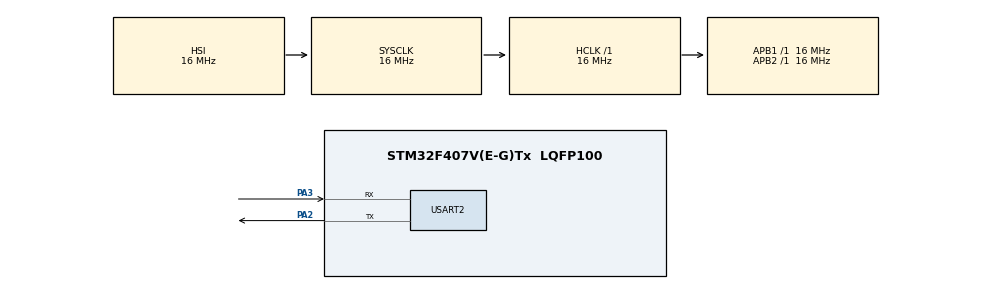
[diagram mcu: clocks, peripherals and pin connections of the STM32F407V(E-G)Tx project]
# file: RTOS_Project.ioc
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Mcu.Family=STM32F4
Mcu.Name=STM32F407V(E-G)Tx
Mcu.Package=LQFP100
NVIC.PriorityGroup=NVIC_PRIORITYGROUP_4
PA13.Mode=Serial_Wire
PA13.Signal=SYS_JTMS-SWDIO
PA14.Mode=Serial_Wire
PA14.Signal=SYS_JTCK-SWCLK
PA2.Mode=Asynchronous
PA2.Signal=USART2_TX
PA3.Mode=Asynchronous
PA3.Signal=USART2_RX
PH0-OSC_IN.Mode=HSE-External-Oscillator
PH0-OSC_IN.Signal=RCC_OSC_IN
PH1-OSC_OUT.Mode=HSE-External-Oscillator
PH1-OSC_OUT.Signal=RCC_OSC_OUT
ProjectManager.HeapSize=0x200
ProjectManager.StackSize=0x400
ProjectManager.TargetToolchain=STM32CubeIDE
RCC.AHBFreq_Value=16000000
RCC.APB1Freq_Value=16000000
RCC.APB2Freq_Value=16000000
RCC.CortexFreq_Value=16000000
RCC.HSE_VALUE=25000000
RCC.HSI_VALUE=16000000
RCC.LSE_VALUE=32768
RCC.SYSCLKFreq_VALUE=16000000
RCC.VCOOutputFreq_Value=192000000
USART2.VirtualMode=VM_ASYNC
board=custom

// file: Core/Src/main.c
/* USER CODE BEGIN Header */
/**
  ******************************************************************************
  * @file           : main.c
  * @brief          : Main program body
  ******************************************************************************
  * @attention
  *
  * <h2><center>&copy; Copyright (c) 2021 STMicroelectronics.
  * All rights reserved.</center></h2>
  *
  * This software component is licensed by ST under BSD 3-Clause license,
  * the "License"; You may not use this file except in compliance with the
  * License. You may obtain a copy of the License at:
  *                        opensource.org/licenses/BSD-3-Clause
  *
  ******************************************************************************
  */
/* USER CODE END Header */
#include "main.h"

/* USER CODE BEGIN Includes */
#include <stdio.h>
#include "FreeRTOS.h"
#include "task.h"
#include "queue.h"

/* USER CODE END Includes */

 UART_HandleTypeDef huart2;

/* USER CODE BEGIN PV */
 TaskHandle_t task1_handle;
 TaskHandle_t task2_handle;
 QueueHandle_t xQueue1;

/* USER CODE END PV */

void SystemClock_Config(void);
static void MX_GPIO_Init(void);
static void MX_USART2_UART_Init(void);
/* USER CODE BEGIN PFP */
void task1_handler(void* parameters);
void task2_handler(void* parameters);

extern  void SEGGER_UART_init(uint32_t);

#ifdef __GNUC__
#define PUTCHAR_PROTOTYPE int __io_putchar(int ch)
#else
#define PUTCHAR_PROTOTYPE int fputc(int ch, FILE *f)
#endif /* __GNUC__ */

/**
  * @brief  Retargets the C library printf function to the USART.
  * @param  None
  * @retval None
  */
PUTCHAR_PROTOTYPE
{
  HAL_UART_Transmit(&huart2, (uint8_t *)&ch, 1, HAL_MAX_DELAY);
  return ch;
}

/* USER CODE END PFP */

int main(void)
{
  /* USER CODE BEGIN 1 */

	BaseType_t status;

  /* USER CODE END 1 */

  /* MCU Configuration--------------------------------------------------------*/

  /* Reset of all peripherals, Initializes the Flash interface and the Systick. */
  HAL_Init();

  /* Configure the system clock */
  SystemClock_Config();

  /* Initialize all configured peripherals */
  MX_GPIO_Init();
  MX_USART2_UART_Init();
  /* USER CODE BEGIN 2 */

  status = xTaskCreate(task1_handler, "Task-1", 200, "Hello world from Task-1", 2, &task1_handle);

  configASSERT(status == pdPASS);

  status = xTaskCreate(task2_handler, "Task-2", 200, "Hello world from Task-2", 2, &task2_handle);

  configASSERT(status == pdPASS);

  xQueue1 = xQueueCreate(5, sizeof(uint8_t) );

  //start the freeRTOS scheduler
  vTaskStartScheduler();
  /* USER CODE END 2 */

  /* Infinite loop */
  while (1)
  {

  }
}

void SystemClock_Config(void)
{
  RCC_OscInitTypeDef RCC_OscInitStruct = {0};
  RCC_ClkInitTypeDef RCC_ClkInitStruct = {0};

  /** Configure the main internal regulator output voltage
  */
  __HAL_RCC_PWR_CLK_ENABLE();
  __HAL_PWR_VOLTAGESCALING_CONFIG(PWR_REGULATOR_VOLTAGE_SCALE1);

  /** Initializes the RCC Oscillators according to the specified parameters
  * in the RCC_OscInitTypeDef structure.
  */
  RCC_OscInitStruct.OscillatorType = RCC_OSCILLATORTYPE_HSI;
  RCC_OscInitStruct.HSIState = RCC_HSI_ON;
  RCC_OscInitStruct.HSICalibrationValue = RCC_HSICALIBRATION_DEFAULT;
  RCC_OscInitStruct.PLL.PLLState = RCC_PLL_NONE;
  if (HAL_RCC_OscConfig(&RCC_OscInitStruct) != HAL_OK)
  {
    Error_Handler();
  }

  /** Initializes the CPU, AHB and APB buses clocks
  */
  RCC_ClkInitStruct.ClockType = RCC_CLOCKTYPE_HCLK|RCC_CLOCKTYPE_SYSCLK
                              |RCC_CLOCKTYPE_PCLK1|RCC_CLOCKTYPE_PCLK2;
  RCC_ClkInitStruct.SYSCLKSource = RCC_SYSCLKSOURCE_HSI;
  RCC_ClkInitStruct.AHBCLKDivider = RCC_SYSCLK_DIV1;
  RCC_ClkInitStruct.APB1CLKDivider = RCC_HCLK_DIV1;
  RCC_ClkInitStruct.APB2CLKDivider = RCC_HCLK_DIV1;

  if (HAL_RCC_ClockConfig(&RCC_ClkInitStruct, FLASH_LATENCY_0) != HAL_OK)
  {
    Error_Handler();
  }
}

static void MX_USART2_UART_Init(void)
{

  huart2.Instance = USART2;
  huart2.Init.BaudRate = 115200;
  huart2.Init.WordLength = UART_WORDLENGTH_8B;
  huart2.Init.StopBits = UART_STOPBITS_1;
  huart2.Init.Parity = UART_PARITY_NONE;
  huart2.Init.Mode = UART_MODE_TX_RX;
  huart2.Init.HwFlowCtl = UART_HWCONTROL_NONE;
  huart2.Init.OverSampling = UART_OVERSAMPLING_16;
  if (HAL_UART_Init(&huart2) != HAL_OK)
  {
    Error_Handler();
  }

}

static void MX_GPIO_Init(void)
{

  /* GPIO Ports Clock Enable */
  __HAL_RCC_GPIOH_CLK_ENABLE();
  __HAL_RCC_GPIOA_CLK_ENABLE();

}

/* USER CODE BEGIN 4 */

void task1_handler(void* parameters)
{	uint8_t data = 0x30;
	while(1)
	{
			xQueueSend( xQueue1 , &data , portMAX_DELAY );
			HAL_UART_Transmit(&huart2, &data , 1 , 10);
			vTaskDelay( pdMS_TO_TICKS( 500 ) );
	}

}

void task2_handler(void* parameters)
{
	while(1)
	{
		uint8_t buffer[5];
		xQueueReceive( xQueue1 , buffer, portMAX_DELAY );
		HAL_UART_Transmit(&huart2, "done" , 4 , HAL_MAX_DELAY);
		//vTaskDelay( pdMS_TO_TICKS( 500 )  );
	}

}

/* USER CODE END 4 */

void Error_Handler(void)
{
  __disable_irq();
  while (1)
  {
  }
}
